# MKW36Z4 register map
Vendor: NXP Semiconductors; Series: Kinetis_W; File version: 1.6
CPU: CM0PLUS r0p0, little endian, no MPU, no FPU, VTOR, 2 interrupt priority bits
Registers are 16-bit, read-write, no defined reset value unless marked. A register's access mark holds for its fields unless they carry their own. Offsets are from the block's base; [hi:lo] are bit positions; {n}, {i} and the like mark numbered series.

## FTFE — Flash Memory Interface
Base 0x40020000; register names take the prefix FTFE_
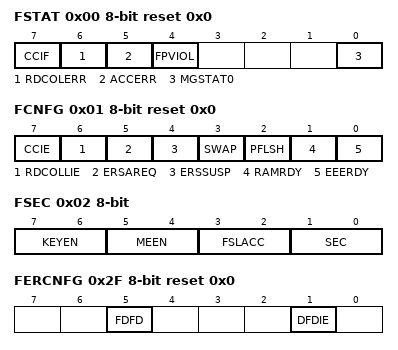
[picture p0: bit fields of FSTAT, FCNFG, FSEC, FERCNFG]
0x00 FSTAT 8-bit reset 0x0 — Flash Status Register
  [7] CCIF — Command Complete Interrupt Flag
    0=FTFE command or EEPROM file system operation in progress; 1=FTFE command or EEPROM file system operation has completed
  [6] RDCOLERR — FTFE Read Collision Error Flag
    0=No collision error detected; 1=Collision error detected
  [5] ACCERR — Flash Access Error Flag
    0=No access error detected; 1=Access error detected
  [4] FPVIOL — Flash Protection Violation Flag
    0=No protection violation detected; 1=Protection violation detected
  [0] MGSTAT0 ro — Memory Controller Command Completion Status Flag
0x01 FCNFG 8-bit reset 0x0 — Flash Configuration Register
  [7] CCIE — Command Complete Interrupt Enable
    0=Command complete interrupt disabled; 1=Command complete interrupt enabled. An interrupt request is generated whenever the FSTAT[CCIF] flag is set.
  [6] RDCOLLIE — Read Collision Error Interrupt Enable
    0=Read collision error interrupt disabled; 1=Read collision error interrupt enabled. An interrupt request is generated whenever an FTFE read collision error is detected (see the description of FSTAT[RDCOLERR]).
  [5] ERSAREQ ro — Erase All Request
    0=No request or request complete; 1=Request to: run the Erase All Blocks command, verify the erased state, program the security byte in the Flash Configuration Field to the unsecure state, and release MCU security by setting the FSEC[SEC] field to the unsecure state
  [4] ERSSUSP — Erase Suspend
    0=No suspend requested; 1=Suspend the current Erase Flash Sector command execution
  [3] SWAP ro
    0=For devices with FlexNVM: Program flash 0 block is located at relative address 0x0000 For devices with program flash only: Program flash 0 block is located at relative address 0x0000; 1=For devices with program flash only: Program flash 1 block is located at relative address 0x0000
  [2] PFLSH ro — FTFE configuration
    0=For devices with FlexNVM: FTFE configuration supports one program flash block and one FlexNVM block For devices with program flash only: Reserved; 1=For devices with FlexNVM: Reserved For devices with program flash only: FTFE configuration supports two program flash blocks
  [1] RAMRDY ro — RAM Ready
    0=For devices with FlexNVM: FlexRAM is not available for traditional RAM access For devices without FlexNVM: Programming acceleration RAM is not available; 1=For devices with FlexNVM: FlexRAM is available as traditional RAM only; writes to the FlexRAM do not trigger EEPROM operations For devices without FlexNVM: Programming acceleration RAM is available
  [0] EEERDY ro — For devices with FlexNVM: This flag indicates if the EEPROM backup data has been copied to the FlexRAM and is therefore available for read access
    0=For devices with FlexNVM: FlexRAM is not available for EEPROM operation For devices without FlexNVM: See RAMRDY for availability of programming acceleration RAM; 1=For devices with FlexNVM: FlexRAM is available for EEPROM operations where: reads from the FlexRAM return data previously written to the FlexRAM in EEPROM mode and writes launch an EEPROM operation to store the written data in the FlexRAM and EEPROM backup For devices without FlexNVM: Reserved
0x02 FSEC 8-bit ro — Flash Security Register
  [7:6] KEYEN — Backdoor Key Security Enable
    0=Backdoor key access disabled; 1=Backdoor key access disabled (preferred KEYEN state to disable backdoor key access); 2=Backdoor key access enabled; 3=Backdoor key access disabled
  [5:4] MEEN — Mass Erase Enable Bits
    0=Mass erase is enabled; 1=Mass erase is enabled; 2=Mass erase is disabled; 3=Mass erase is enabled
  [3:2] FSLACC — Factory Security Level Access Code
    0=Factory access granted; 1=Factory access denied; 2=Factory access denied; 3=Factory access granted
  [1:0] SEC — Flash Security
    0=MCU security status is secure; 1=MCU security status is secure; 2=MCU security status is unsecure (The standard shipping condition of the FTFE is unsecure.); 3=MCU security status is secure
0x03 FOPT 8-bit ro — Flash Option Register
  [7:0] OPT — Nonvolatile Option
0x04 FCCOB{x} (x=3,2,1,0,7,6,5,4,B,A,9,8; step 0x1) 8-bit reset 0x0 — Flash Common Command Object Registers
  [7:0] CCOBn — The FCCOB register provides a command code and relevant parameters to the memory controller
0x10 FPROT{x} (x=3,2,1,0; step 0x1) 8-bit — Program Flash Protection Registers
  [7:0] PROT — Program Flash Region Protect
    0=Program flash region is protected; 1=Program flash region is not protected
0x16 FEPROT 8-bit — EEPROM Protection Register
  [7:0] EPROT — EEPROM Region Protect
    0=For devices with program flash only: Reserved For devices with FlexNVM: EEPROM region is protected; 1=For devices with program flash only: Reserved For devices with FlexNVM: EEPROM region is not protected
0x17 FDPROT 8-bit — Data Flash Protection Register
  [7:0] DPROT — Data Flash Region Protect
    0=Data Flash region is protected; 1=Data Flash region is not protected
0x18 XACC{x} (x=H3,H2,H1,H0,L3,L2,L1,L0; step 0x1) 8-bit ro — Execute-only Access Registers
  [7:0] XA — Execute-only access control
    0=Associated segment is accessible in execute mode only (as an instruction fetch); 1=Associated segment is accessible as data or in execute mode
0x20 SACC{x} (x=H3,H2,H1,H0,L3,L2,L1,L0; step 0x1) 8-bit ro — Supervisor-only Access Registers
  [7:0] SA — Supervisor-only access control
    0=Associated segment is accessible in supervisor mode only; 1=Associated segment is accessible in user or supervisor mode
0x28 FACSS 8-bit ro — Flash Access Segment Size Register
  [7:0] SGSIZE — Segment Size
0x2B FACSN 8-bit ro — Flash Access Segment Number Register
  [7:0] NUMSG — Number of Segments Indicator
    48=Program flash memory is divided into 48 segments (768 Kbytes, 1.5 Mbytes); 64=Program flash memory is divided into 64 segments (256 Kbytes, 512 Kbytes, 1 Mbyte, 2 Mbytes)
0x2E FERSTAT 8-bit reset 0x0 — Flash Error Status Register
  [1] DFDIF — Double Bit Fault Detect Interrupt Flag
    0=Double bit fault not detected during a valid flash read access from the platform flash controller; 1=Double bit fault detected (or FERCNFG[FDFD] is set) during a valid flash read access from the platform flash controller
0x2F FERCNFG 8-bit reset 0x0 — Flash Error Configuration Register
  [5] FDFD — Force Double Bit Fault Detect
    0=FERSTAT[DFDIF] sets only if a double bit fault is detected during read access from the platform flash controller; 1=FERSTAT[DFDIF] sets during any valid flash read access from the platform flash controller. An interrupt request is generated if the DFDIE bit is set.
  [1] DFDIE — Double Bit Fault Detect Interrupt Enable
    0=Double bit fault detect interrupt disabled; 1=Double bit fault detect interrupt enabled. An interrupt request is generated whenever the FERSTAT[DFDIF] flag is set.
